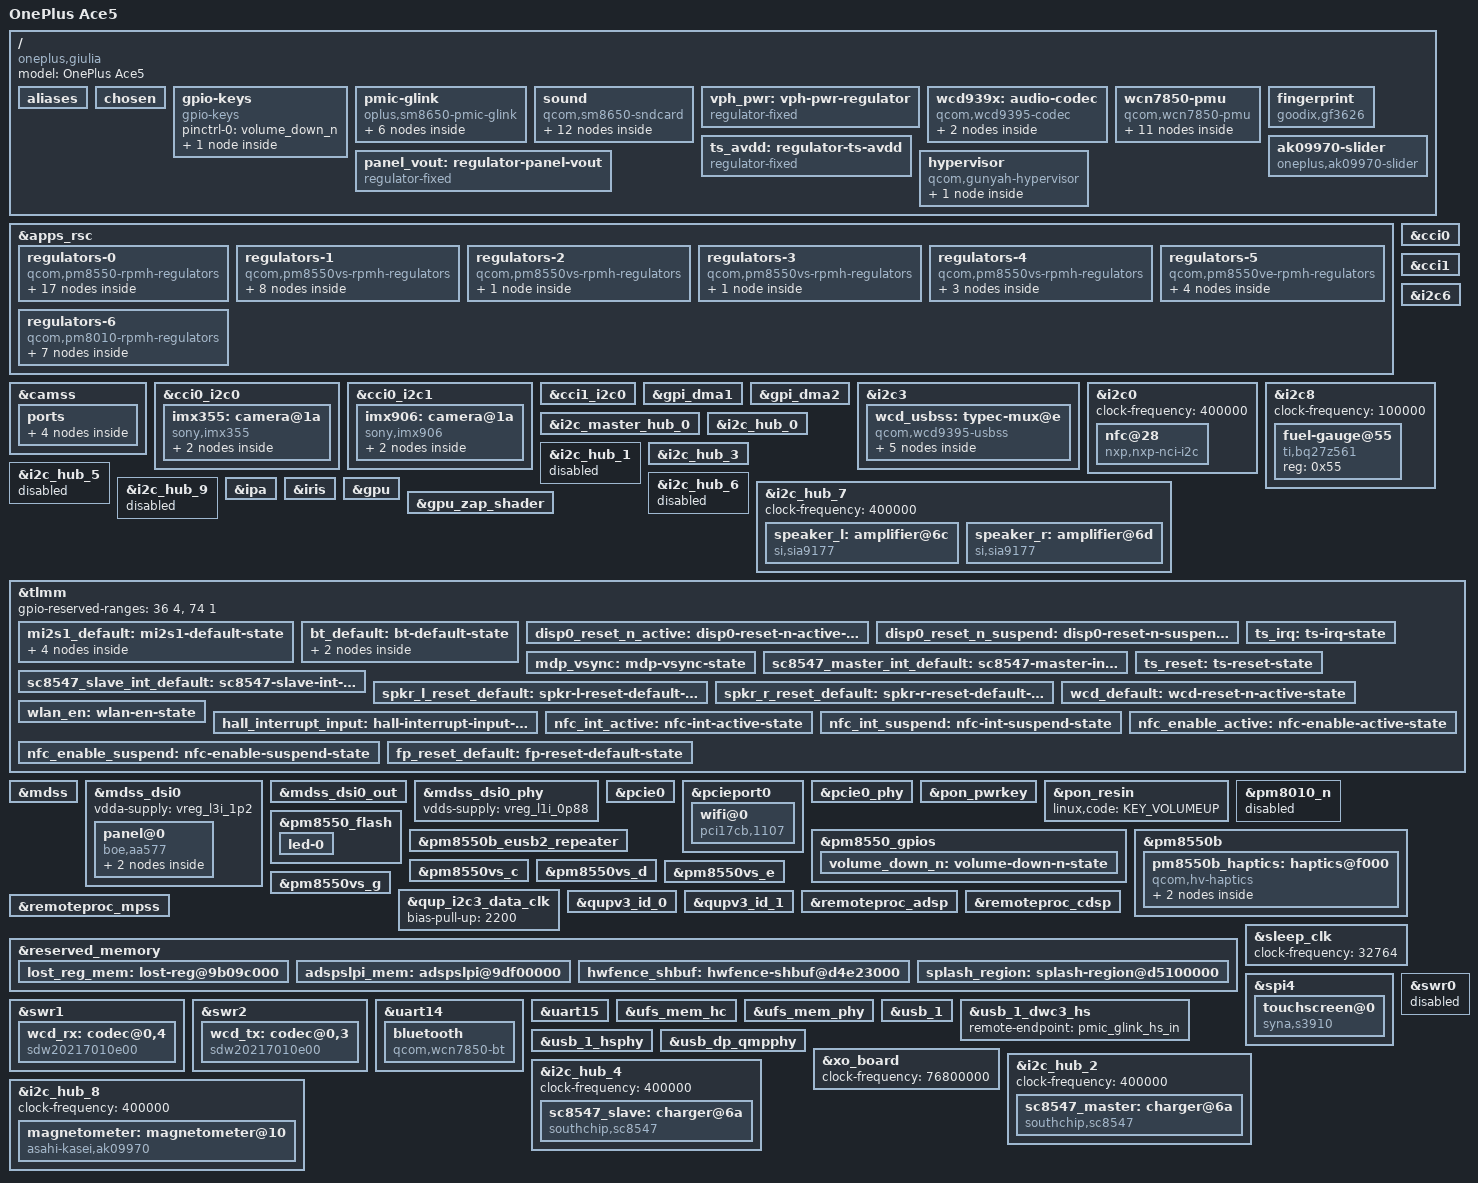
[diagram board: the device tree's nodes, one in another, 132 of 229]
// SPDX-License-Identifier: BSD-3-Clause

/dts-v1/;

#include <dt-bindings/leds/common.h>
#include <dt-bindings/media/video-interfaces.h>
#include <dt-bindings/clock/qcom,sm8650-camcc.h>
#include <dt-bindings/pinctrl/qcom,pmic-gpio.h>
#include <dt-bindings/regulator/qcom,rpmh-regulator.h>
#include <dt-bindings/sound/qcom,q6dsp-lpass-ports.h>
#include "sm8650.dtsi"
#include "pm8010.dtsi"
#include "pm8550.dtsi"
#include "pm8550b.dtsi"
#define PMK8550VE_SID 8
#include "pm8550ve.dtsi"
#include "pm8550vs.dtsi"
#include "pmk8550.dtsi"
#include "pmr735d_a.dtsi"

/* /delete-node/ &rmtfs_mem; */
/delete-node/ &hwfence_shbuf;
/delete-node/ &adspslpi_mem;

/ {
	model = "OnePlus Ace5";
	compatible = "oneplus,giulia", "qcom,sm8650";

	aliases {
		serial0 = &uart15;
		serial1 = &uart14;
	};

	chosen {
		/* stdout-path = "serial0:115200n8"; */
	};

	gpio-keys {
		compatible = "gpio-keys";

		pinctrl-names = "default";
		pinctrl-0 = <&volume_down_n>;

		key-volume-down {
			label = "Volume Down";
			linux,code = <KEY_VOLUMEDOWN>;
			gpios = <&pm8550_gpios 6 GPIO_ACTIVE_LOW>;
			debounce-interval = <15>;
			linux,can-disable;
			wakeup-source;
		};
	};

	pmic-glink {
		compatible = "oplus,sm8650-pmic-glink",
					 "qcom,sm8650-pmic-glink",
					 "qcom,sm8550-pmic-glink",
					 "qcom,pmic-glink";
		#address-cells = <1>;
		#size-cells = <0>;

		orientation-gpios = <&tlmm 29 GPIO_ACTIVE_HIGH>;

		/*
		 * OnePlus PPS charge-pump bring-up gates (qcom_battmgr OnePlus
		 * PPS patch).  The 2:1 policy service requires the whole chain:
		 * read-buffer -> fixed-5V -> 5.5V -> 9V -> 2:1 ramp -> 5m run ->
		 * policy, with auto-start.  The secondary/dual gates are left
		 * disabled; enable them only when testing the dual-pump path.
		 */
		oneplus,pps-read-buffer;
		oneplus,pps-fixed-5v;
		oneplus,pps-5v5-1a;
		oneplus,pps-ramp-9v-1a;
		oneplus,pps-ramp-9v2-1a;
		oneplus,pps-ramp-2to1-1a;
		oneplus,pps-run-2to1-5m;
		oneplus,pps-policy-2to1-1a;
		oneplus,pps-secondary-500ms;
		oneplus,pps-dual-500ms;

		connector@0 {
			compatible = "usb-c-connector";
			reg = <0>;

			power-role = "dual";
			data-role = "dual";

			ports {
				#address-cells = <1>;
				#size-cells = <0>;

				port@0 {
					reg = <0>;

					pmic_glink_hs_in: endpoint {
						remote-endpoint = <&usb_1_dwc3_hs>;
					};
				};

				port@2 {
					reg = <2>;

					pmic_glink_sbu: endpoint {
						remote-endpoint = <&wcd_usbss_sbu_mux>;
					};
				};
			};
		};
	};

	sound {
		compatible = "qcom,sm8650-sndcard", "qcom,sm8450-sndcard";
		model = "oneplus-giulia";

		pinctrl-names = "default";
		pinctrl-0 = <&mi2s1_default>;

		audio-routing = "IN1_HPHL", "HPHL_OUT",
						"IN2_HPHR", "HPHR_OUT",
						"AMIC1", "MIC BIAS1",
						"AMIC2", "MIC BIAS2",
						"AMIC3", "MIC BIAS4",
						"AMIC4", "MIC BIAS3",
						"AMIC5", "MIC BIAS1",
						"TX SWR_INPUT0", "ADC1_OUTPUT",
						"TX SWR_INPUT1", "ADC2_OUTPUT",
						"TX SWR_INPUT2", "ADC3_OUTPUT",
						"TX SWR_INPUT3", "ADC4_OUTPUT";

		wcd-playback-dai-link {
			link-name = "WCD Playback";

			cpu {
				sound-dai = <&q6apmbedai RX_CODEC_DMA_RX_0>;
			};

			codec {
				sound-dai = <&wcd939x 0>, <&swr1 0>, <&lpass_rxmacro 0>;
			};

			platform {
				sound-dai = <&q6apm>;
			};
		};

		wcd-capture-dai-link {
			link-name = "WCD Capture";

			cpu {
				sound-dai = <&q6apmbedai TX_CODEC_DMA_TX_3>;
			};

			codec {
				sound-dai = <&wcd939x 1>, <&swr2 0>, <&lpass_txmacro 0>;
			};

			platform {
				sound-dai = <&q6apm>;
			};
		};

		/*
		 * Speakers: 2x SI-IN SIA9177 smart PA on Secondary MI2S.
		 * giulia has no WSA884x.
		 */
		mi2s-dai-link {
			link-name = "MI2S Secondary Playback";

			cpu {
				sound-dai = <&q6apmbedai SECONDARY_MI2S_RX>;
			};

			platform {
				sound-dai = <&q6apm>;
			};

			codec {
				sound-dai = <&speaker_l>, <&speaker_r>;
			};
		};
	};

	vph_pwr: vph-pwr-regulator {
		compatible = "regulator-fixed";

		regulator-name = "vph_pwr";
		regulator-min-microvolt = <3700000>;
		regulator-max-microvolt = <3700000>;

		regulator-always-on;
		regulator-boot-on;
	};

	wcd939x: audio-codec {
		compatible = "qcom,wcd9395-codec", "qcom,wcd9390-codec";

		pinctrl-names = "default";
		pinctrl-0 = <&wcd_default>;

		qcom,micbias1-microvolt = <1800000>;
		qcom,micbias2-microvolt = <1800000>;
		qcom,micbias3-microvolt = <1800000>;
		qcom,micbias4-microvolt = <1800000>;
		qcom,mbhc-buttons-vthreshold-microvolt = <75000 150000 237000 500000 500000 500000 500000 500000>;
		qcom,mbhc-headset-vthreshold-microvolt = <1700000>;
		qcom,mbhc-headphone-vthreshold-microvolt = <50000>;
		qcom,rx-device = <&wcd_rx>;
		qcom,tx-device = <&wcd_tx>;

		reset-gpios = <&tlmm 107 GPIO_ACTIVE_LOW>;

		vdd-buck-supply = <&vreg_l15b_1p8>;
		vdd-rxtx-supply = <&vreg_l15b_1p8>;
		vdd-io-supply = <&vreg_l15b_1p8>;
		vdd-mic-bias-supply = <&vreg_bob1>;

		#sound-dai-cells = <1>;

		mode-switch;
		orientation-switch;

		port {
			wcd_codec_headset_in: endpoint {
				remote-endpoint = <&wcd_usbss_headset_out>;
			};
		};
	};

	wcn7850-pmu {
		compatible = "qcom,wcn7850-pmu";

		pinctrl-names = "default";
		pinctrl-0 = <&wlan_en>, <&bt_default>;

		wlan-enable-gpios = <&tlmm 16 GPIO_ACTIVE_HIGH>;
		bt-enable-gpios = <&tlmm 17 GPIO_ACTIVE_HIGH>;

		vdd-supply = <&vreg_s4i_0p85>;
		vddio-supply = <&vreg_l15b_1p8>;
		vddio1p2-supply = <&vreg_l3c_1p2>;
		vddaon-supply = <&vreg_s2c_0p8>;
		vdddig-supply = <&vreg_s3c_0p9>;
		vddrfa1p2-supply = <&vreg_s1c_1p2>;
		vddrfa1p8-supply = <&vreg_s6c_1p8>;

		clocks = <&rpmhcc RPMH_RF_CLK1>;

		regulators {
			vreg_pmu_rfa_cmn: ldo0 {
				regulator-name = "vreg_pmu_rfa_cmn";
			};

			vreg_pmu_aon_0p59: ldo1 {
				regulator-name = "vreg_pmu_aon_0p59";
			};

			vreg_pmu_wlcx_0p8: ldo2 {
				regulator-name = "vreg_pmu_wlcx_0p8";
			};

			vreg_pmu_wlmx_0p85: ldo3 {
				regulator-name = "vreg_pmu_wlmx_0p85";
			};

			vreg_pmu_btcmx_0p85: ldo4 {
				regulator-name = "vreg_pmu_btcmx_0p85";
			};

			vreg_pmu_rfa_0p8: ldo5 {
				regulator-name = "vreg_pmu_rfa_0p8";
			};

			vreg_pmu_rfa_1p2: ldo6 {
				regulator-name = "vreg_pmu_rfa_1p2";
			};

			vreg_pmu_rfa_1p8: ldo7 {
				regulator-name = "vreg_pmu_rfa_1p8";
			};

			vreg_pmu_pcie_0p9: ldo8 {
				regulator-name = "vreg_pmu_pcie_0p9";
			};

			vreg_pmu_pcie_1p8: ldo9 {
				regulator-name = "vreg_pmu_pcie_1p8";
			};
		};
	};

	/* Panel VCI output enable */
	panel_vout: regulator-panel-vout {
		compatible = "regulator-fixed";

		regulator-name = "panel_vout";

		gpio = <&tlmm 91 GPIO_ACTIVE_HIGH>;
		enable-active-high;
	};

	/* Touch analog rail behind GPIO 108 */
	ts_avdd: regulator-ts-avdd {
		compatible = "regulator-fixed";

		regulator-name = "ts_avdd";
		regulator-min-microvolt = <3008000>;
		regulator-max-microvolt = <3008000>;

		gpio = <&tlmm 108 GPIO_ACTIVE_HIGH>;
		enable-active-high;
	};

	/*
	 * Goodix under-display optical fingerprint sensor (UFF), driven from
	 * QSEE in TEE mode: the SPI bus and all biometric logic belong to the
	 * secure world, so the AP only owns the supply, the reset line and no
	 * interrupt.  Finger events are delivered to userspace by the
	 * touchscreen, which is why there is no "interrupts" here.
	 *
	 * "firmware-name" is the trusted application the QSEECOM TEE driver
	 * loads from the vendor firmware; on giulia the optical part is a
	 * Jiiov JV0301, whose TA is "uff_jv" (/odm/vendor/firmware/uff_jv.mdt).
	 *
	 * NOTE: the real part is a GW in-display sensor; "goodix,gf3626" is
	 * used here as the reference driver's tested compatible until the
	 * exact part is known.
	 */
	fingerprint {
		compatible = "goodix,gf3626";

		reset-gpios = <&tlmm 89 GPIO_ACTIVE_LOW>;
		vdd-supply = <&vreg_l14b_3p2>;

		firmware-name = "uff_jv";

		pinctrl-names = "default";
		pinctrl-0 = <&fp_reset_default>;
	};
};

&apps_rsc {
	regulators-0 {
		compatible = "qcom,pm8550-rpmh-regulators";
		qcom,pmic-id = "b";

		vdd-bob1-supply = <&vph_pwr>;
		vdd-bob2-supply = <&vph_pwr>;
		vdd-l2-l13-l14-supply = <&vreg_bob1>;
		vdd-l3-supply = <&vreg_s1c_1p2>;
		vdd-l5-l16-supply = <&vreg_bob1>;
		vdd-l6-l7-supply = <&vreg_bob1>;
		vdd-l8-l9-supply = <&vreg_bob1>;
		vdd-l11-supply = <&vreg_s1c_1p2>;
		vdd-l12-supply = <&vreg_s6c_1p8>;
		vdd-l15-supply = <&vreg_s6c_1p8>;
		vdd-l17-supply = <&vreg_bob2>;

		vreg_bob1: bob1 {
			regulator-name = "vreg_bob1";
			regulator-min-microvolt = <3296000>;
			regulator-max-microvolt = <3960000>;
			regulator-initial-mode = <RPMH_REGULATOR_MODE_HPM>;
		};

		vreg_bob2: bob2 {
			regulator-name = "vreg_bob2";
			regulator-min-microvolt = <2720000>;
			regulator-max-microvolt = <3008000>;
			regulator-initial-mode = <RPMH_REGULATOR_MODE_HPM>;
		};

		vreg_l1b_1p8: ldo1 {
			regulator-name = "vreg_l1b_1p8";
			regulator-min-microvolt = <1800000>;
			regulator-max-microvolt = <1800000>;
			regulator-initial-mode = <RPMH_REGULATOR_MODE_HPM>;
		};

		vreg_l2b_3p0: ldo2 {
			regulator-name = "vreg_l2b_3p0";
			regulator-min-microvolt = <3008000>;
			regulator-max-microvolt = <3008000>;
			regulator-initial-mode = <RPMH_REGULATOR_MODE_HPM>;
			regulator-allow-set-load;
			regulator-allowed-modes = <RPMH_REGULATOR_MODE_LPM
									   RPMH_REGULATOR_MODE_HPM>;
		};

		vreg_l4b_1p8: ldo4 {
			regulator-name = "vreg_l4b_1p8";
			regulator-min-microvolt = <1800000>;
			regulator-max-microvolt = <1800000>;
			regulator-initial-mode = <RPMH_REGULATOR_MODE_HPM>;
		};

		vreg_l5b_3p1: ldo5 {
			regulator-name = "vreg_l5b_3p1";
			regulator-min-microvolt = <3104000>;
			regulator-max-microvolt = <3104000>;
			regulator-initial-mode = <RPMH_REGULATOR_MODE_HPM>;
			regulator-allow-set-load;
			regulator-allowed-modes = <RPMH_REGULATOR_MODE_LPM
									   RPMH_REGULATOR_MODE_HPM>;
		};

		vreg_l6b_1p8: ldo6 {
			regulator-name = "vreg_l6b_1p8";
			regulator-min-microvolt = <1800000>;
			regulator-max-microvolt = <3008000>;
			regulator-initial-mode = <RPMH_REGULATOR_MODE_HPM>;
			regulator-allow-set-load;
			regulator-allowed-modes = <RPMH_REGULATOR_MODE_LPM
									   RPMH_REGULATOR_MODE_HPM>;
		};

		vreg_l7b_1p8: ldo7 {
			regulator-name = "vreg_l7b_1p8";
			regulator-min-microvolt = <1800000>;
			regulator-max-microvolt = <3008000>;
			regulator-initial-mode = <RPMH_REGULATOR_MODE_HPM>;
		};

		vreg_l8b_1p8: ldo8 {
			regulator-name = "vreg_l8b_1p8";
			regulator-min-microvolt = <1800000>;
			regulator-max-microvolt = <3008000>;
			regulator-initial-mode = <RPMH_REGULATOR_MODE_HPM>;
			regulator-allow-set-load;
			regulator-allowed-modes = <RPMH_REGULATOR_MODE_LPM
									   RPMH_REGULATOR_MODE_HPM>;
		};

		vreg_l9b_2p9: ldo9 {
			regulator-name = "vreg_l9b_2p9";
			regulator-min-microvolt = <2960000>;
			regulator-max-microvolt = <3008000>;
			regulator-initial-mode = <RPMH_REGULATOR_MODE_HPM>;
			regulator-allow-set-load;
			regulator-allowed-modes = <RPMH_REGULATOR_MODE_LPM
									   RPMH_REGULATOR_MODE_HPM>;
		};

		vreg_l11b_1p2: ldo11 {
			regulator-name = "vreg_l11b_1p2";
			regulator-min-microvolt = <1200000>;
			regulator-max-microvolt = <1504000>;
			regulator-initial-mode = <RPMH_REGULATOR_MODE_HPM>;
			regulator-allow-set-load;
			regulator-allowed-modes = <RPMH_REGULATOR_MODE_LPM
									   RPMH_REGULATOR_MODE_HPM>;
		};

		vreg_l12b_1p8: ldo12 {
			regulator-name = "vreg_l12b_1p8";
			regulator-min-microvolt = <1800000>;
			regulator-max-microvolt = <1800000>;
			regulator-initial-mode = <RPMH_REGULATOR_MODE_HPM>;
			regulator-allow-set-load;
			regulator-allowed-modes = <RPMH_REGULATOR_MODE_LPM
									   RPMH_REGULATOR_MODE_HPM>;
		};

		vreg_l13b_3p0: ldo13 {
			regulator-name = "vreg_l13b_3p0";
			regulator-min-microvolt = <3000000>;
			regulator-max-microvolt = <3000000>;
			regulator-initial-mode = <RPMH_REGULATOR_MODE_HPM>;
			regulator-allow-set-load;
			regulator-allowed-modes = <RPMH_REGULATOR_MODE_LPM
									   RPMH_REGULATOR_MODE_HPM>;
		};

		vreg_l14b_3p2: ldo14 {
			regulator-name = "vreg_l14b_3p2";
			regulator-min-microvolt = <3200000>;
			regulator-max-microvolt = <3200000>;
			regulator-initial-mode = <RPMH_REGULATOR_MODE_HPM>;
			regulator-allow-set-load;
			regulator-allowed-modes = <RPMH_REGULATOR_MODE_LPM
									   RPMH_REGULATOR_MODE_HPM>;
		};

		vreg_l15b_1p8: ldo15 {
			regulator-name = "vreg_l15b_1p8";
			regulator-min-microvolt = <1800000>;
			regulator-max-microvolt = <1800000>;
			regulator-initial-mode = <RPMH_REGULATOR_MODE_HPM>;
			regulator-allow-set-load;
			regulator-allowed-modes = <RPMH_REGULATOR_MODE_LPM
									   RPMH_REGULATOR_MODE_HPM>;
		};

		vreg_l16b_2p8: ldo16 {
			regulator-name = "vreg_l16b_2p8";
			regulator-min-microvolt = <2800000>;
			regulator-max-microvolt = <2800000>;
			regulator-initial-mode = <RPMH_REGULATOR_MODE_HPM>;
			regulator-allow-set-load;
			regulator-allowed-modes = <RPMH_REGULATOR_MODE_LPM
									   RPMH_REGULATOR_MODE_HPM>;
		};

		vreg_l17b_2p5: ldo17 {
			regulator-name = "vreg_l17b_2p5";
			regulator-min-microvolt = <2504000>;
			regulator-max-microvolt = <2504000>;
			regulator-initial-mode = <RPMH_REGULATOR_MODE_HPM>;
			regulator-allow-set-load;
			regulator-allowed-modes = <RPMH_REGULATOR_MODE_LPM
									   RPMH_REGULATOR_MODE_HPM>;
		};
	};

	regulators-1 {
		compatible = "qcom,pm8550vs-rpmh-regulators";
		qcom,pmic-id = "c";

		vdd-l1-supply = <&vreg_s1c_1p2>;
		vdd-l2-supply = <&vreg_s1c_1p2>;
		vdd-l3-supply = <&vreg_s1c_1p2>;
		vdd-s1-supply = <&vph_pwr>;
		vdd-s2-supply = <&vph_pwr>;
		vdd-s3-supply = <&vph_pwr>;
		vdd-s4-supply = <&vph_pwr>;
		vdd-s5-supply = <&vph_pwr>;
		vdd-s6-supply = <&vph_pwr>;

		vreg_s1c_1p2: smps1 {
			regulator-name = "vreg_s1c_1p2";
			regulator-min-microvolt = <1256000>;
			regulator-max-microvolt = <1348000>;
			regulator-initial-mode = <RPMH_REGULATOR_MODE_HPM>;
		};

		vreg_s2c_0p8: smps2 {
			regulator-name = "vreg_s2c_0p8";
			regulator-min-microvolt = <852000>;
			regulator-max-microvolt = <1036000>;
			regulator-initial-mode = <RPMH_REGULATOR_MODE_HPM>;
		};

		vreg_s3c_0p9: smps3 {
			regulator-name = "vreg_s3c_0p9";
			regulator-min-microvolt = <976000>;
			regulator-max-microvolt = <1064000>;
			regulator-initial-mode = <RPMH_REGULATOR_MODE_HPM>;
		};

		vreg_s4c_1p2: smps4 {
			regulator-name = "vreg_s4c_1p2";
			regulator-min-microvolt = <1224000>;
			regulator-max-microvolt = <1280000>;
			regulator-initial-mode = <RPMH_REGULATOR_MODE_HPM>;
		};

		vreg_s5c_0p7: smps5 {
			regulator-name = "vreg_s5c_0p7";
			regulator-min-microvolt = <752000>;
			regulator-max-microvolt = <900000>;
			regulator-initial-mode = <RPMH_REGULATOR_MODE_HPM>;
		};

		vreg_s6c_1p8: smps6 {
			regulator-name = "vreg_s6c_1p8";
			regulator-min-microvolt = <1856000>;
			regulator-max-microvolt = <2000000>;
			regulator-initial-mode = <RPMH_REGULATOR_MODE_HPM>;
		};

		vreg_l1c_1p2: ldo1 {
			regulator-name = "vreg_l1c_1p2";
			regulator-min-microvolt = <1200000>;
			regulator-max-microvolt = <1200000>;
			regulator-initial-mode = <RPMH_REGULATOR_MODE_HPM>;
			regulator-allow-set-load;
			regulator-allowed-modes = <RPMH_REGULATOR_MODE_LPM
									   RPMH_REGULATOR_MODE_HPM>;
		};

		vreg_l3c_1p2: ldo3 {
			regulator-name = "vreg_l3c_1p2";
			regulator-min-microvolt = <1200000>;
			regulator-max-microvolt = <1200000>;
			regulator-initial-mode = <RPMH_REGULATOR_MODE_HPM>;
			regulator-allow-set-load;
			regulator-allowed-modes = <RPMH_REGULATOR_MODE_LPM
									   RPMH_REGULATOR_MODE_HPM>;
		};
	};

	regulators-2 {
		compatible = "qcom,pm8550vs-rpmh-regulators";
		qcom,pmic-id = "d";

		vdd-l1-supply = <&vreg_s3c_0p9>;

		vreg_l1d_0p88: ldo1 {
			regulator-name = "vreg_l1d_0p88";
			regulator-min-microvolt = <912000>;
			regulator-max-microvolt = <920000>;
			regulator-initial-mode = <RPMH_REGULATOR_MODE_HPM>;
			regulator-allow-set-load;
			regulator-allowed-modes = <RPMH_REGULATOR_MODE_LPM
									   RPMH_REGULATOR_MODE_HPM>;
		};
	};

	regulators-3 {
		compatible = "qcom,pm8550vs-rpmh-regulators";
		qcom,pmic-id = "e";

		vdd-l3-supply = <&vreg_s3c_0p9>;

		vreg_l3e_0p9: ldo3 {
			regulator-name = "vreg_l3e_0p9";
			regulator-min-microvolt = <880000>;
			regulator-max-microvolt = <920000>;
			regulator-initial-mode = <RPMH_REGULATOR_MODE_HPM>;
			regulator-allow-set-load;
			regulator-allowed-modes = <RPMH_REGULATOR_MODE_LPM
									   RPMH_REGULATOR_MODE_HPM>;
		};
	};

	regulators-4 {
		compatible = "qcom,pm8550vs-rpmh-regulators";
		qcom,pmic-id = "g";

		vdd-l1-supply = <&vreg_s3c_0p9>;
		vdd-l3-supply = <&vreg_s3c_0p9>;

		vreg_l1g_0p91: ldo1 {
			regulator-name = "vreg_l1g_0p91";
			regulator-min-microvolt = <912000>;
			regulator-max-microvolt = <920000>;
			regulator-initial-mode = <RPMH_REGULATOR_MODE_HPM>;
			regulator-allow-set-load;
			regulator-allowed-modes = <RPMH_REGULATOR_MODE_LPM
									   RPMH_REGULATOR_MODE_HPM>;
		};

		/* camera dvdd for the ultrawide (downstream pm_v6g_l2, 1.2 V) */
		vreg_l2g_1p2: ldo2 {
			regulator-name = "vreg_l2g_1p2";
			regulator-always-on;
			regulator-min-microvolt = <1200000>;
			regulator-max-microvolt = <1200000>;
			regulator-initial-mode = <RPMH_REGULATOR_MODE_HPM>;
			regulator-allow-set-load;
			regulator-allowed-modes = <RPMH_REGULATOR_MODE_LPM
									   RPMH_REGULATOR_MODE_HPM>;
		};

		vreg_l3g_0p91: ldo3 {
			regulator-name = "vreg_l3g_0p91";
			regulator-min-microvolt = <880000>;
			regulator-max-microvolt = <912000>;
			regulator-initial-mode = <RPMH_REGULATOR_MODE_HPM>;
			regulator-allow-set-load;
			regulator-allowed-modes = <RPMH_REGULATOR_MODE_LPM
									   RPMH_REGULATOR_MODE_HPM>;
		};
	};

	regulators-5 {
		compatible = "qcom,pm8550ve-rpmh-regulators";
		qcom,pmic-id = "i";

		vdd-l1-supply = <&vreg_s3c_0p9>;
		vdd-l2-supply = <&vreg_s3c_0p9>;
		vdd-l3-supply = <&vreg_s1c_1p2>;
		vdd-s4-supply = <&vph_pwr>;

		vreg_s4i_0p85: smps4 {
			regulator-name = "vreg_s4i_0p85";
			regulator-min-microvolt = <852000>;
			regulator-max-microvolt = <1004000>;
			regulator-initial-mode = <RPMH_REGULATOR_MODE_HPM>;
		};

		vreg_l1i_0p88: ldo1 {
			regulator-name = "vreg_l1i_0p88";
			regulator-min-microvolt = <880000>;
			regulator-max-microvolt = <912000>;
			regulator-initial-mode = <RPMH_REGULATOR_MODE_HPM>;
			regulator-allow-set-load;
			regulator-allowed-modes = <RPMH_REGULATOR_MODE_LPM
									   RPMH_REGULATOR_MODE_HPM>;
		};

		vreg_l2i_0p88: ldo2 {
			regulator-name = "vreg_l2i_0p88";
			regulator-min-microvolt = <880000>;
			regulator-max-microvolt = <912000>;
			regulator-initial-mode = <RPMH_REGULATOR_MODE_HPM>;
			regulator-allow-set-load;
			regulator-allowed-modes = <RPMH_REGULATOR_MODE_LPM
									   RPMH_REGULATOR_MODE_HPM>;
		};

		vreg_l3i_1p2: ldo3 {
			regulator-name = "vreg_l3i_0p91";
			regulator-min-microvolt = <1200000>;
			regulator-max-microvolt = <1200000>;
			regulator-initial-mode = <RPMH_REGULATOR_MODE_HPM>;
			regulator-allow-set-load;
			regulator-allowed-modes = <RPMH_REGULATOR_MODE_LPM
									   RPMH_REGULATOR_MODE_HPM>;
		};
	};

	regulators-6 {
		compatible = "qcom,pm8010-rpmh-regulators";
		qcom,pmic-id = "m";

		vdd-l1-l2-supply = <&vreg_s1c_1p2>;
		vdd-l3-l4-supply = <&vreg_bob2>;
		vdd-l5-supply = <&vreg_s6c_1p8>;
		vdd-l6-supply = <&vreg_bob1>;
		vdd-l7-supply = <&vreg_bob1>;

		vreg_l1m_1p1: ldo1 {
			regulator-name = "vreg_l1m_1p1";
			regulator-min-microvolt = <1104000>;
			regulator-max-microvolt = <1104000>;
			regulator-initial-mode = <RPMH_REGULATOR_MODE_HPM>;
			regulator-allow-set-load;
			regulator-allowed-modes = <RPMH_REGULATOR_MODE_LPM
									   RPMH_REGULATOR_MODE_HPM>;
		};

		vreg_l2m_1p056: ldo2 {
			regulator-name = "vreg_l2m_1p056";
			regulator-min-microvolt = <1056000>;
			regulator-max-microvolt = <1056000>;
			regulator-initial-mode = <RPMH_REGULATOR_MODE_HPM>;
			regulator-allow-set-load;
			regulator-allowed-modes = <RPMH_REGULATOR_MODE_LPM
									   RPMH_REGULATOR_MODE_HPM>;
		};

		vreg_l3m_2p8: ldo3 {
			regulator-name = "vreg_l3m_2p8";
			regulator-min-microvolt = <2800000>;
			regulator-max-microvolt = <2800000>;
			regulator-initial-mode = <RPMH_REGULATOR_MODE_HPM>;
		};

		vreg_l4m_2p8: ldo4 {
			regulator-name = "vreg_l4m_2p8";
			regulator-always-on;
			regulator-min-microvolt = <2800000>;
			regulator-max-microvolt = <2800000>;
			regulator-initial-mode = <RPMH_REGULATOR_MODE_HPM>;
		};

		vreg_l5m_1p8: ldo5 {
			regulator-name = "vreg_l5m_1p8";
			regulator-always-on;
			regulator-min-microvolt = <1800000>;
			regulator-max-microvolt = <1800000>;
			regulator-initial-mode = <RPMH_REGULATOR_MODE_HPM>;
		};

		/* giulia: L6M is 1.8 V (downstream pm8010m_l6 init-voltage), not
		 * the 2.8 V the reference board uses. */
		vreg_l6m_1p8: ldo6 {
			regulator-name = "vreg_l6m_1p8";
			regulator-min-microvolt = <1800000>;
			regulator-max-microvolt = <1800000>;
			regulator-initial-mode = <RPMH_REGULATOR_MODE_HPM>;
		};

		vreg_l7m_2p96: ldo7 {
			regulator-name = "vreg_l7m_2p96";
			regulator-min-microvolt = <2960000>;
			regulator-max-microvolt = <2960000>;
			regulator-initial-mode = <RPMH_REGULATOR_MODE_HPM>;
		};
	};

	/* pm8010_n isn't present */
};

/*
 * Cameras on giulia: 50MP main (Sony IMX906 / LYT-700), 8MP ultrawide
 * (Sony IMX355) and a 2MP macro, powered by the pm8010m rails.
 *
 * Bringup target: the ultrawide IMX355 (has a mainline driver).
 * Downstream truth (qcom,cam-sensor1): CCI0 master 0 (SDA/SCL gpio113/114),
 * CSI PHY0, MCLK2 (gpio102, 19.2 MHz), reset gpio14,
 * vana 2.8V (pm8010m_l4), vdig 1.2V (pm_v6g_l2), vio 1.8V (pm8010m_l5).
 */
&camss {
	vdd-csiphy01-0p9-supply = <&vreg_l2i_0p88>;
	vdd-csiphy01-1p2-supply = <&vreg_l3i_1p2>;
	vdd-csiphy35-0p9-supply = <&vreg_l2i_0p88>;
	vdd-csiphy35-1p2-supply = <&vreg_l3i_1p2>;

	status = "okay";

	ports {
		port@0 {
			csiphy0_ep: endpoint {
				data-lanes = <0 1 2 3>;
				remote-endpoint = <&imx355_ep>;
			};
		};

		port@1 {
			csiphy1_ep: endpoint {
				data-lanes = <0 1 2>;
				remote-endpoint = <&imx906_ep>;
			};
		};
	};
};

&cci0 {
	status = "okay";
};

/* 8MP ultrawide: Sony IMX355 */
&cci0_i2c0 {
	imx355: camera@1a {
		compatible = "sony,imx355";
		reg = <0x1a>;

		clocks = <&camcc CAM_CC_MCLK2_CLK>;
		assigned-clocks = <&camcc CAM_CC_MCLK2_CLK>;
		assigned-clock-rates = <19200000>;

		reset-gpios = <&tlmm 14 GPIO_ACTIVE_LOW>;
		pinctrl-0 = <&cam2_default>;
		pinctrl-1 = <&cam2_sleep>;
		pinctrl-names = "default", "sleep";

		avdd-supply = <&vreg_l4m_2p8>;
		dvdd-supply = <&vreg_l2g_1p2>;
		dovdd-supply = <&vreg_l5m_1p8>;

		port {
			imx355_ep: endpoint {
				remote-endpoint = <&csiphy0_ep>;
				data-lanes = <0 1 2 3>;
				link-frequencies = /bits/ 64 <360000000>;
			};
		};
	};
};

/* 50MP main: Sony IMX906 (LYT-700).  Bring-up scaffold (P1). */
&cci0_i2c1 {
	imx906: camera@1a {
		compatible = "sony,imx906";
		reg = <0x1a>;

		clocks = <&camcc CAM_CC_MCLK1_CLK>;
		assigned-clocks = <&camcc CAM_CC_MCLK1_CLK>;
		assigned-clock-rates = <19200000>;
		power-domains = <&camcc CAM_CC_TITAN_TOP_GDSC>;

		reset-gpios = <&tlmm 82 GPIO_ACTIVE_LOW>;
		pinctrl-0 = <&cam1_default>;
		pinctrl-1 = <&cam1_sleep>;
		pinctrl-names = "default", "sleep";

		avdd-supply = <&vreg_l6m_1p8>;
		dvdd-supply = <&vreg_l1m_1p1>;
		dovdd-supply = <&vreg_l5m_1p8>;
		vaf-supply = <&vreg_l7m_2p96>;
		v_custom1-supply = <&vreg_l3m_2p8>;
		v_custom2-supply = <&vreg_l7m_2p96>;

		port {
			imx906_ep: endpoint {
				remote-endpoint = <&csiphy1_ep>;
				bus-type = <MEDIA_BUS_TYPE_CSI2_CPHY>;
				data-lanes = <0 1 2>;
				link-frequencies = /bits/ 64 <2490000000>;
			};
		};
	};
};

&cci1 {
	status = "okay";
};

/* TODO: 50MP main (imx906) and 2MP macro sensors */
&cci1_i2c0 {
};

&gpi_dma1 {
	status = "okay";
};

&gpi_dma2 {
	status = "okay";
};

&i2c3 {
	status = "okay";

	wcd_usbss: typec-mux@e {
		compatible = "qcom,wcd9395-usbss", "qcom,wcd9390-usbss";
		reg = <0xe>;

		vdd-supply = <&vreg_l15b_1p8>;

		mode-switch;
		orientation-switch;

		ports {
			#address-cells = <1>;
			#size-cells = <0>;

			port@0 {
				reg = <0>;

				wcd_usbss_sbu_mux: endpoint {
					remote-endpoint = <&pmic_glink_sbu>;
				};
			};

			port@1 {
				reg = <1>;

				wcd_usbss_headset_out: endpoint {
					remote-endpoint = <&wcd_codec_headset_in>;
				};
			};
		};
	};
};

/*
 * Unlike QRD (USB retimer), giulia's i2c6 carries the NFC controller
 * (downstream "nq@64", NXP NQ/SN NCI family). Add once basic bringup works.
 */
&i2c6 {
	status = "okay";
};

/*
 * NFC: NXP SN220T on qupv3_se0_i2c, which is mainline &i2c0 (0xa80000) @ 0x28.
 * VEN=gpio34, CLKREQ=gpio35, IRQ=gpio75.  The SN220 reference clock is fed by
 * the PMIC in hardware (requested via CLKREQ), so no AP-side clock is needed.
 * Mainline driver: nxp-nci-i2c (nxp,nxp-nci-i2c).
 */
&i2c0 {
	status = "okay";
	clock-frequency = <400000>;

	nfc@28 {
		compatible = "nxp,nxp-nci-i2c";
		reg = <0x28>;

		interrupt-parent = <&tlmm>;
		interrupts = <75 IRQ_TYPE_LEVEL_HIGH>;

		enable-gpios = <&tlmm 34 GPIO_ACTIVE_HIGH>;

		pinctrl-names = "default";
		pinctrl-0 = <&nfc_int_active>, <&nfc_enable_active>;
	};
};

&i2c8 {
	status = "okay";
	clock-frequency = <100000>;

	fuel-gauge@55 {
		compatible = "ti,bq27z561";
		reg = <0x55>;
	};
};

&i2c_master_hub_0 {
	status = "okay";
};

/*
 * Motion sensors (accel/gyro/alsps/mag) are not described in the AP
 * device tree: downstream the SLPI drives them over the QUP I2C master
 * hub. Bring up the hub instances the stock AP tree leaves disabled so
 * the AP can probe which chips are actually wired there.
 */
&i2c_hub_0 {
	status = "okay";
};

/*
 * hub_1 (984000), hub_6 (998000) and hub_9 (9a4000) fault with a
 * synchronous external abort on the very first SE register read.  This is
 * not caused by the ADSP/SSC firmware (verified with remoteproc_adsp
 * disabled) nor by the GCC clocks; those SEs are simply not accessible
 * from the AP.  Keep them disabled so a single fault cannot abort the whole
 * geni-i2c module load and block the remaining hub SEs.
 */
&i2c_hub_1 {
	status = "disabled";
};

&i2c_hub_3 {
	status = "okay";
};

/*
 * hub_5 (994000) uses GPIO 74/75, but gpio74 is in gpio-reserved-ranges,
 * so its pinctrl always fails with -EINVAL.  Disable it to avoid the noise.
 * (gpio75 is used by the NFC IRQ below.)
 */
&i2c_hub_5 {
	status = "disabled";
};

&i2c_hub_6 {
	status = "disabled";
};

&i2c_hub_9 {
	status = "disabled";
};

&i2c_hub_7 {
	clock-frequency = <400000>; /* downstream qcom,clk-freq-out = 400 kHz */

	status = "okay";

	/* SI-IN SIA9177 smart PAs, downstream sipa91xx_i2c@6c/@6d */
	speaker_l: amplifier@6c {
		compatible = "si,sia9177";
		reg = <0x6c>;

		reset-gpios = <&tlmm 173 GPIO_ACTIVE_HIGH>;

		si,channel = <0>;
		sound-name-prefix = "SpkrLeft";
		#sound-dai-cells = <0>;

		pinctrl-names = "default";
		pinctrl-0 = <&spkr_l_reset_default>;
	};

	speaker_r: amplifier@6d {
		compatible = "si,sia9177";
		reg = <0x6d>;

		reset-gpios = <&tlmm 178 GPIO_ACTIVE_HIGH>;

		si,channel = <1>;
		sound-name-prefix = "SpkrRight";
		#sound-dai-cells = <0>;

		pinctrl-names = "default";
		pinctrl-0 = <&spkr_r_reset_default>;
	};
};

&ipa {
	qcom,gsi-loader = "self";
	memory-region = <&ipa_fw_mem>;
	firmware-name = "qcom/sm8650/oneplus/giulia/ipa_fws.mbn";
	status = "okay";
};

&iris {
	status = "okay";
};

&gpu {
	status = "okay";
};

&gpu_zap_shader {
	firmware-name = "qcom/sm8650/oneplus/giulia/gen70900_zap.mbn";
};

/*
 * &lpass_tlmm {
 *	   Secondary MI2S out to the SIA9177 PAs. Downstream drives these
 *	   pins from LPI TDM1 (gpio6 sck / gpio7 ws / gpio8 data).
 *	   If the build errors on the function names, check
 *	   drivers/pinctrl/qcom/pinctrl-sm8650-lpass-lpi.c (i2s1_* vs mi2s1_*).
 *
 *	   mi2s1_default: mi2s1-default-state {
 *		   sck-pins {
 *			   pins = "gpio6";
 *			   function = "i2s1_clk";
 *			   drive-strength = <8>;
 *			   bias-disable;
 *		   };
 *
 *		   ws-pins {
 *			   pins = "gpio7";
 *			   function = "i2s1_ws";
 *			   drive-strength = <8>;
 *			   bias-disable;
 *		   };
 *
 *		   data-pins {
 *			   pins = "gpio8";
 *			   function = "i2s1_data";
 *			   drive-strength = <8>;
 *			   bias-disable;
 *		   };
 *	   };
 * };
 */

&tlmm {
	gpio-reserved-ranges = <36 4>, <74 1>;

	mi2s1_default: mi2s1-default-state {
		sck-pins {
			pins = "gpio121";
			function = "i2s1_sck";
			drive-strength = <8>;
			bias-disable;
		};

		ws-pins {
			pins = "gpio123";
			function = "i2s1_ws";
			drive-strength = <8>;
			bias-disable;
		};

		data0-pins {
			pins = "gpio122";
			function = "i2s1_data0";
			drive-strength = <8>;
			bias-disable;
		};

		data1-pins {
			pins = "gpio124";
			function = "i2s1_data1";
			drive-strength = <8>;
			bias-disable;
		};
	};

	bt_default: bt-default-state {
		bt-en-pins {
			pins = "gpio17";
			function = "gpio";
			drive-strength = <16>;
			bias-disable;
		};

		sw-ctrl-pins {
			pins = "gpio18";
			function = "gpio";
			bias-pull-down;
		};
	};

	disp0_reset_n_active: disp0-reset-n-active-state {
		pins = "gpio133";
		function = "gpio";
		drive-strength = <8>;
		bias-disable;
	};

	disp0_reset_n_suspend: disp0-reset-n-suspend-state {
		pins = "gpio133";
		function = "gpio";
		drive-strength = <2>;
		bias-pull-down;
	};

	mdp_vsync: mdp-vsync-state {
		pins = "gpio86";
		function = "mdp_vsync";
		drive-strength = <2>;
		bias-pull-down;
	};

	sc8547_master_int_default: sc8547-master-int-default-state {
		pins = "gpio8";
		function = "gpio";
		drive-strength = <2>;
		bias-pull-up;
		input-enable;
	};

	sc8547_slave_int_default: sc8547-slave-int-default-state {
		pins = "gpio15";
		function = "gpio";
		drive-strength = <2>;
		bias-pull-up;
		input-enable;
	};

	spkr_l_reset_default: spkr-l-reset-default-state {
		pins = "gpio173";
		function = "gpio";
		drive-strength = <2>;
		bias-disable;
	};

	spkr_r_reset_default: spkr-r-reset-default-state {
		pins = "gpio178";
		function = "gpio";
		drive-strength = <2>;
		bias-disable;
	};

	ts_irq: ts-irq-state {
		pins = "gpio162";
		function = "gpio";
		drive-strength = <8>;
		bias-pull-up;
		output-disable;
	};

	ts_reset: ts-reset-state {
		pins = "gpio161";
		function = "gpio";
		drive-strength = <8>;
		bias-pull-up;
	};

	wcd_default: wcd-reset-n-active-state {
		pins = "gpio107";
		function = "gpio";
		drive-strength = <16>;
		bias-disable;
		output-low;
	};

	wlan_en: wlan-en-state {
		pins = "gpio16";
		function = "gpio";
		drive-strength = <8>;
		bias-pull-down;
	};
};

&mdss {
	status = "okay";
};

&mdss_dsi0 {
	vdda-supply = <&vreg_l3i_1p2>;
	status = "okay";

	panel@0 {
		compatible = "boe,aa577";
		reg = <0>;

		vddio-supply = <&vreg_l12b_1p8>;
		vci-supply = <&vreg_l13b_3p0>;
		vout-supply = <&panel_vout>;

		reset-gpios = <&tlmm 133 GPIO_ACTIVE_LOW>;

		pinctrl-names = "default", "sleep";
		pinctrl-0 = <&disp0_reset_n_active>, <&mdp_vsync>;
		pinctrl-1 = <&disp0_reset_n_suspend>, <&mdp_vsync>;

		port {
			panel0_in: endpoint {
				remote-endpoint = <&mdss_dsi0_out>;
			};
		};
	};
};

&mdss_dsi0_out {
	remote-endpoint = <&panel0_in>;
	data-lanes = <0 1 2 3>;
};

&mdss_dsi0_phy {
	vdds-supply = <&vreg_l1i_0p88>;
	status = "okay";
};

&pcie0 {
	wake-gpios = <&tlmm 96 GPIO_ACTIVE_HIGH>;
	perst-gpios = <&tlmm 94 GPIO_ACTIVE_LOW>;

	pinctrl-names = "default";
	pinctrl-0 = <&pcie0_default_state>;

	status = "okay";
};

&pcieport0 {
	wifi@0 {
		compatible = "pci17cb,1107";
		reg = <0x10000 0x0 0x0 0x0 0x0>;

		vddrfacmn-supply = <&vreg_pmu_rfa_cmn>;
		vddaon-supply = <&vreg_pmu_aon_0p59>;
		vddwlcx-supply = <&vreg_pmu_wlcx_0p8>;
		vddwlmx-supply = <&vreg_pmu_wlmx_0p85>;
		vddrfa0p8-supply = <&vreg_pmu_rfa_0p8>;
		vddrfa1p2-supply = <&vreg_pmu_rfa_1p2>;
		vddrfa1p8-supply = <&vreg_pmu_rfa_1p8>;
		vddpcie0p9-supply = <&vreg_pmu_pcie_0p9>;
		vddpcie1p8-supply = <&vreg_pmu_pcie_1p8>;
	};
};

&pcie0_phy {
	vdda-phy-supply = <&vreg_l1i_0p88>;
	vdda-pll-supply = <&vreg_l3i_1p2>;

	status = "okay";
};

&pon_pwrkey {
	status = "okay";
};

&pon_resin {
	linux,code = <KEY_VOLUMEUP>;

	status = "okay";
};

/* Not present on giulia */
&pm8010_n {
	status = "disabled";
};

&pm8550_flash {
	status = "okay";

	/* TODO: verify LED channels/currents from downstream flash node */
	led-0 {
		function = LED_FUNCTION_FLASH;
		color = <LED_COLOR_ID_WHITE>;
		led-sources = <1>, <4>;
		led-max-microamp = <500000>;
		flash-max-microamp = <2000000>;
		flash-max-timeout-us = <1280000>;
	};
};

&pm8550_gpios {
	volume_down_n: volume-down-n-state {
		pins = "gpio6";
		function = "normal";
		bias-pull-up;
		input-enable;
		power-source = <1>;
	};
};

&pm8550b_eusb2_repeater {
	vdd18-supply = <&vreg_l15b_1p8>;
	vdd3-supply = <&vreg_l5b_3p1>;
};

/*
 * PM8550B High-Voltage Haptics (HAP525_HV) driving the LRA.
 * CFG / PTN / HBST register bases are the three reg entries.
 * Values taken from the downstream giulia node.
 */
&pm8550b {
	pm8550b_haptics: haptics@f000 {
		compatible = "qcom,hv-haptics";
		reg = <0xf000 0xf100 0xf200>;

		interrupts = <0x7 0xf0 0x1 IRQ_TYPE_EDGE_RISING>;
		interrupt-names = "fifo-empty";

		qcom,vmax-mv = <1260>;
		qcom,cl-vmax-mv = <1260>;
		qcom,fifo-vmax-mv = <7700>;
		qcom,old-steady-vmax-mv = <7700>;
		qcom,brake-mode = <0>;
		qcom,brake-pattern = /bits/ 8 <0xff 0x3f 0x1f>;
		qcom,lra-period-us = <5882>;
		qcom,drv-sig-shape = <1>;
		qcom,brake-sig-shape = <1>;
		qcom,fifo-empty-threshold = <480>;
		qcom,vibrator-type = <809>;
		qcom,cal-data-restore;

		qcom,hap-swr-slave-reg {
			regulator-name = "hap-swr-slave-reg";
		};

		/*
		 * Preloaded pattern effect; enables FF_PERIODIC/FF_CUSTOM and
		 * the pattern playback path.  Tuple = <amplitude(<=0x1ff)
		 * period(0..6) f_lra_x2(0|1)>.
		 */
		effect-click {
			qcom,effect-id = <0>;
			qcom,wf-vmax-mv = <1800>;
			qcom,wf-pattern-preload;
			qcom,wf-pattern-data = <0x1ff 0x00 0x00>,
					       <0x1ff 0x00 0x01>,
					       <0x1ff 0x01 0x00>,
					       <0x180 0x02 0x00>;
		};
	};
};

&pm8550vs_c {
	status = "okay";
};

&pm8550vs_d {
	status = "okay";
};

&pm8550vs_e {
	status = "okay";
};

&pm8550vs_g {
	status = "okay";
};

&qup_i2c3_data_clk {
	/* Use internal I2C pull-up */
	bias-pull-up = <2200>;
};

&qupv3_id_0 {
	status = "okay";
};

&qupv3_id_1 {
	status = "okay";
};

&remoteproc_adsp {
	firmware-name = "qcom/sm8650/oneplus/giulia/adsp.mbn",
					"qcom/sm8650/oneplus/giulia/adsp_dtb.mbn";

	status = "okay";
};

&remoteproc_cdsp {
	firmware-name = "qcom/sm8650/oneplus/giulia/cdsp.mbn",
					"qcom/sm8650/oneplus/giulia/cdsp_dtb.mbn";

	status = "okay";
};

&remoteproc_mpss {
	firmware-name = "qcom/sm8650/oneplus/giulia/modem.mbn",
					"qcom/sm8650/oneplus/giulia/modem_dtb.mbn";

	status = "okay";
};

&reserved_memory {
	lost_reg_mem: lost-reg@9b09c000 {
		reg = <0x0 0x9b09c000 0x0 0x4000>;
		no-map;
	};

	adspslpi_mem: adspslpi@9df00000 {
		reg = <0x0 0x9df00000 0x0 0x5280000>;
		no-map;
	};

	hwfence_shbuf: hwfence-shbuf@d4e23000 {
		reg = <0x0 0xd4e23000 0x0 0x2dd000>;
		no-map;
	};

	splash_region: splash-region@d5100000 {
		label = "cont_splash_region";
		reg = <0x0 0xd5100000 0x0 0x2b00000>;
		no-map;
	};
};

&sleep_clk {
	clock-frequency = <32764>;
};

&spi4 {
	status = "okay";

	touchscreen@0 {
		compatible = "syna,s3910";
		reg = <0>;
		spi-max-frequency = <19000000>;

		interrupts-extended = <&tlmm 162 IRQ_TYPE_LEVEL_LOW>;

		reset-gpios = <&tlmm 161 GPIO_ACTIVE_LOW>;

		/*
		 * Downstream vdd-supply phandle resolves to pm_humu_l4 (LDO B4,
		 * 1.8V) = vreg_l4b_1p8 in upstream sm8650 naming, NOT L12B.
		 */
		vdd-supply = <&vreg_l4b_1p8>;
		avdd-supply = <&ts_avdd>;

		pinctrl-names = "default";
		pinctrl-0 = <&ts_irq>, <&ts_reset>;

		/*
		 * NOTE: do NOT add touchscreen-size-x/y = <1264/2780> here.
		 * Firmware reports coordinates in 1/16 pixel units
		 * (max_x/max_y ~ 20223 x 44479, taken from the chip at probe);
		 * userspace scales automatically from the reported abs range.
		 */
	};
};

&swr0 {
	status = "disabled";

	/* giulia does not have WSA884x */
};

&swr1 {
	status = "okay";

	/* WCD9395 RX */
	wcd_rx: codec@0,4 {
		compatible = "sdw20217010e00";
		reg = <0 4>;

		/*
		 * WCD9395 RX Port 1 (HPH_L/R)		<=> SWR1 Port 1 (HPH_L/R)
		 * WCD9395 RX Port 2 (CLSH)			<=> SWR1 Port 2 (CLSH)
		 * WCD9395 RX Port 3 (COMP_L/R)		<=> SWR1 Port 3 (COMP_L/R)
		 * WCD9395 RX Port 4 (LO)			<=> SWR1 Port 4 (LO)
		 * WCD9395 RX Port 5 (DSD_L/R)		<=> SWR1 Port 5 (DSD_L/R)
		 * WCD9395 RX Port 6 (HIFI_PCM_L/R) <=> SWR1 Port 9 (HIFI_PCM_L/R)
		 */
		qcom,rx-port-mapping = <1 2 3 4 5 9>;
	};
};

&swr2 {
	status = "okay";

	/* WCD9395 TX */
	wcd_tx: codec@0,3 {
		compatible = "sdw20217010e00";
		reg = <0 3>;

		/*
		 * WCD9395 TX Port 1 (ADC1,2,3,4)		  <=> SWR2 Port 2 (TX SWR_INPUT 0,1,2,3)
		 * WCD9395 TX Port 2 (ADC3,4 & DMIC0,1)	  <=> SWR2 Port 2 (TX SWR_INPUT 0,1,2,3)
		 * WCD9395 TX Port 3 (DMIC0,1,2,3 & MBHC) <=> SWR2 Port 3 (TX SWR_INPUT 4,5,6,7)
		 * WCD9395 TX Port 4 (DMIC4,5,6,7)		  <=> SWR2 Port 4 (TX SWR_INPUT 8,9,10,11)
		 */
		qcom,tx-port-mapping = <2 2 3 4>;
	};
};

&uart14 {
	status = "okay";

	bluetooth {
		compatible = "qcom,wcn7850-bt";

		vddrfacmn-supply = <&vreg_pmu_rfa_cmn>;
		vddaon-supply = <&vreg_pmu_aon_0p59>;
		vddwlcx-supply = <&vreg_pmu_wlcx_0p8>;
		vddwlmx-supply = <&vreg_pmu_wlmx_0p85>;
		vddrfa0p8-supply = <&vreg_pmu_rfa_0p8>;
		vddrfa1p2-supply = <&vreg_pmu_rfa_1p2>;
		vddrfa1p8-supply = <&vreg_pmu_rfa_1p8>;

		max-speed = <3200000>;
	};
};

&uart15 {
	status = "okay";
};

&ufs_mem_hc {
	reset-gpios = <&tlmm 210 GPIO_ACTIVE_LOW>;

	vcc-supply = <&vreg_l17b_2p5>;
	vcc-max-microamp = <1300000>;
	vccq-supply = <&vreg_l1c_1p2>;
	vccq-max-microamp = <1200000>;

	status = "okay";
};

&ufs_mem_phy {
	vdda-phy-supply = <&vreg_l1d_0p88>;
	vdda-pll-supply = <&vreg_l3i_1p2>;

	status = "okay";
};

/*
 * DPAUX -> WCD9395 -> USB_SBU -> USB-C
 * eUSB2 DP/DM -> PM85550HS -> eUSB2 DP/DM -> WCD9395 -> USB-C
 * USB SS -> NB7VPQ904MMUTWG -> USB-C
 */

&usb_1 {
	dr_mode = "otg";
	usb-role-switch;
	maximum-speed = "high-speed";

	status = "okay";
};

&usb_1_dwc3_hs {
	remote-endpoint = <&pmic_glink_hs_in>;
};

&usb_1_hsphy {
	vdd-supply = <&vreg_l1i_0p88>;
	vdda12-supply = <&vreg_l3i_1p2>;

	phys = <&pm8550b_eusb2_repeater>;

	status = "okay";
};

&usb_dp_qmpphy {
	vdda-phy-supply = <&vreg_l3i_1p2>;
	vdda-pll-supply = <&vreg_l3g_0p91>;

	status = "okay";
};

&xo_board {
	clock-frequency = <76800000>;
};

/* ---------- SC8547 双电荷泵 ---------- */
&i2c_hub_2 {
	status = "okay";
	clock-frequency = <400000>;

	sc8547_master: charger@6a {
		compatible = "southchip,sc8547";
		reg = <0x6a>;

		southchip,master;
		southchip,role = "primary";
		southchip,psy-name = "sc8547-primary";

		/*
		 * Development bring-up: expose the SC8547D charge-pump write
		 * path used by the qcom_battmgr OnePlus PPS patch.  The raw
		 * protection profile matches the downstream SC8547D
		 * sc8547_init_device() image; the voltage window is derived from
		 * the validated 2:1 envelope (7.3-9.4 V input, 3.60-4.35 V cell,
		 * start target 2*VBAT + 0.45 V with 0.20 V overshoot, 70 C die).
		 * Re-validate these bounds on giulia before daily use.
		 */
		southchip,allow-experimental-control;
		southchip,allow-experimental-cp-enable;
		southchip,allow-experimental-cp-pulse;

		southchip,experimental-reg00 = <0x36>; /* BAT OVP  */
		southchip,experimental-reg01 = <0xbf>; /* BAT OCP  */
		southchip,experimental-reg02 = <0x01>; /* AC OVP   */
		southchip,experimental-reg04 = <0x50>; /* VBUS OVP */
		southchip,experimental-reg05 = <0x1e>; /* IBUS OCP */
		southchip,experimental-reg0d = <0x70>; /* PMID2OUT */

		southchip,experimental-vbus-min-uv = <6200000>;
		southchip,experimental-vbus-max-uv = <9400000>;
		southchip,experimental-vbat-min-uv = <3000000>;
		southchip,experimental-vbat-max-uv = <4350000>;
		southchip,experimental-pulse-vbus-min-uv = <6200000>;
		southchip,experimental-start-delta-uv = <450000>;
		southchip,experimental-start-overshoot-max-uv = <200000>;
		southchip,experimental-start-reference-max-uv = <4350000>;
		southchip,experimental-pulse-ratio-error-max-uv = <250000>;
		southchip,experimental-tdie-max-mc = <70000>;

		ovp_reg = <0x36>;
		ocp_reg = <0x0e>;
		oplus,pps_ocp_max = <3600>;

		interrupt-parent = <&tlmm>;
		interrupts = <8 IRQ_TYPE_EDGE_FALLING>;

		pinctrl-names = "default";
		pinctrl-0 = <&sc8547_master_int_default>;
	};
};

&i2c_hub_4 {
	status = "okay";
	clock-frequency = <400000>;

	sc8547_slave: charger@6a {
		compatible = "southchip,sc8547";
		reg = <0x6a>;

		southchip,role = "secondary";
		southchip,psy-name = "sc8547-secondary";

		/* Same development opt-in / SC8547D image as the primary. */
		southchip,allow-experimental-control;
		southchip,allow-experimental-cp-enable;
		southchip,allow-experimental-cp-pulse;

		southchip,experimental-reg00 = <0x36>;
		southchip,experimental-reg01 = <0xbf>;
		southchip,experimental-reg02 = <0x01>;
		southchip,experimental-reg04 = <0x50>;
		southchip,experimental-reg05 = <0x1e>;
		southchip,experimental-reg0d = <0x70>;

		southchip,experimental-vbus-min-uv = <6200000>;
		southchip,experimental-vbus-max-uv = <9400000>;
		southchip,experimental-vbat-min-uv = <3000000>;
		southchip,experimental-vbat-max-uv = <4500000>;
		southchip,experimental-pulse-vbus-min-uv = <6200000>;
		southchip,experimental-start-delta-uv = <450000>;
		southchip,experimental-start-overshoot-max-uv = <200000>;
		southchip,experimental-start-reference-max-uv = <4350000>;
		southchip,experimental-pulse-ratio-error-max-uv = <250000>;
		southchip,experimental-tdie-max-mc = <70000>;

		ovp_reg = <0x36>;
		ocp_reg = <0x0e>;
		oplus,pps_ocp_max = <3600>;

		interrupt-parent = <&tlmm>;
		interrupts = <15 IRQ_TYPE_EDGE_FALLING>;

		pinctrl-names = "default";
		pinctrl-0 = <&sc8547_slave_int_default>;
	};
};

/* ---------- AK09970 hall-effect slider ---------- */
&i2c_hub_8 {
	status = "okay";
	clock-frequency = <400000>;

	magnetometer: magnetometer@10 {
		compatible = "asahi-kasei,ak09970";
		reg = <0x10>;

		vdd-supply = <&vreg_l1b_1p8>;
		vddio-supply = <&vreg_l1b_1p8>;

		#io-channel-cells = <1>;

		pinctrl-names = "default";
		pinctrl-0 = <&hall_interrupt_input>;
	};
};

/ {
    ak09970-slider {
    	compatible = "oneplus,ak09970-slider";
    
    	io-channels = <&magnetometer 0>,
    		      <&magnetometer 1>,
    		      <&magnetometer 2>;
    	io-channel-names = "x", "y", "z";
    
    	oneplus,up-threshold = <5000>;
    	oneplus,mid-threshold = <22000>;
    
    	interrupt-parent = <&tlmm>;
    	interrupts = <99 IRQ_TYPE_LEVEL_LOW>;
	};
};

&tlmm {
	hall_interrupt_input: hall-interrupt-input-state {
		pins = "gpio99";
		function = "gpio";
		drive-strength = <2>;
		bias-pull-up;
		input-enable;
	};

	/* NXP SN220T NFC: IRQ (gpio75), VEN (gpio34) + CLKREQ (gpio35) */
	nfc_int_active: nfc-int-active-state {
		pins = "gpio75";
		function = "gpio";
		drive-strength = <2>;
		bias-pull-down;
	};

	nfc_int_suspend: nfc-int-suspend-state {
		pins = "gpio75";
		function = "gpio";
		drive-strength = <2>;
		bias-pull-down;
	};

	nfc_enable_active: nfc-enable-active-state {
		pins = "gpio34", "gpio35";
		function = "gpio";
		drive-strength = <2>;
		bias-disable;
	};

	nfc_enable_suspend: nfc-enable-suspend-state {
		pins = "gpio34", "gpio35";
		function = "gpio";
		drive-strength = <2>;
		bias-disable;
	};

	/* Goodix UFF fingerprint reset: GPIO89, held low (asserted) by default */
	fp_reset_default: fp-reset-default-state {
		pins = "gpio89";
		function = "gpio";
		drive-strength = <2>;
		bias-disable;
		output-low;
	};
};

/ {
    hypervisor {
        compatible = "qcom,gunyah-hypervisor", "gunyah-hypervisor", "simple-bus";
        #address-cells = <2>;
        #size-cells = <0>;
    
	gunyah-resource-mgr@831f2ab7189a43c1 {
	    compatible = "gunyah-resource-manager";
	    reg = <0x831f2ab7 0x189a43c1>,
	          <0x831f2ab7 0x189a807c>;
	    interrupts = <GIC_SPI 0x3a0 IRQ_TYPE_EDGE_RISING 0>,  /* 末尾多一个 0 */
	                 <GIC_SPI 0x3a1 IRQ_TYPE_EDGE_RISING 0>;
	};
    };
};
